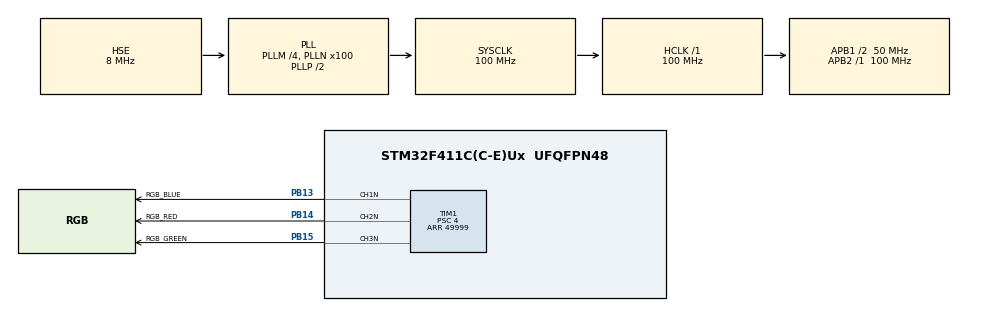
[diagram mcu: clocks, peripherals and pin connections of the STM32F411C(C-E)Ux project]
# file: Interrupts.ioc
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Mcu.Family=STM32F4
Mcu.Name=STM32F411C(C-E)Ux
Mcu.Package=UFQFPN48
NVIC.PriorityGroup=NVIC_PRIORITYGROUP_4
NVIC.TIM1_UP_TIM10_IRQn=true\:0\:0\:false\:false\:true\:true\:true\:true
PB13.GPIO_Label=RGB_BLUE
PB13.Mode=PWM Generation1 CH1N
PB13.Signal=TIM1_CH1N
PB14.GPIO_Label=RGB_RED
PB14.Mode=PWM Generation2 CH2N
PB14.Signal=TIM1_CH2N
PB15.GPIO_Label=RGB_GREEN
PB15.Mode=PWM Generation3 CH3N
PB15.Signal=TIM1_CH3N
PH0\ -\ OSC_IN.Mode=HSE-External-Oscillator
PH0\ -\ OSC_IN.Signal=RCC_OSC_IN
PH1\ -\ OSC_OUT.Mode=HSE-External-Oscillator
PH1\ -\ OSC_OUT.Signal=RCC_OSC_OUT
ProjectManager.HeapSize=0x200
ProjectManager.StackSize=0x400
ProjectManager.TargetToolchain=STM32CubeIDE
RCC.48MHZClocksFreq_Value=50000000
RCC.AHBFreq_Value=100000000
RCC.APB1CLKDivider=RCC_HCLK_DIV2
RCC.APB1Freq_Value=50000000
RCC.APB1TimFreq_Value=100000000
RCC.APB2Freq_Value=100000000
RCC.APB2TimFreq_Value=100000000
RCC.CortexFreq_Value=100000000
RCC.HCLKFreq_Value=100000000
RCC.HSE_VALUE=8000000
RCC.HSI_VALUE=16000000
RCC.LSE_VALUE=32768
RCC.PLLM=4
RCC.PLLN=100
RCC.PLLSourceVirtual=RCC_PLLSOURCE_HSE
RCC.SYSCLKFreq_VALUE=100000000
RCC.SYSCLKSource=RCC_SYSCLKSOURCE_PLLCLK
RCC.VCOOutputFreq_Value=200000000
TIM1.Channel-PWM\ Generation1\ CH1N=TIM_CHANNEL_1
TIM1.Channel-PWM\ Generation2\ CH2N=TIM_CHANNEL_2
TIM1.Channel-PWM\ Generation3\ CH3N=TIM_CHANNEL_3
TIM1.OCNPolarity_1=TIM_OCNPOLARITY_LOW
TIM1.OCNPolarity_2=TIM_OCNPOLARITY_LOW
TIM1.OCNPolarity_3=TIM_OCNPOLARITY_LOW
TIM1.Period=49999
TIM1.Prescaler=4
TIM10.Period=9999
TIM10.Prescaler=99
VP_TIM10_VS_ClockSourceINT.Mode=Enable_Timer
VP_TIM1_VS_ClockSourceINT.Mode=Internal
board=custom

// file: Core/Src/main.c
/* USER CODE BEGIN Header */
/**
  ******************************************************************************
  * @file           : main.c
  * @brief          : Main program body
  ******************************************************************************
  * @attention
  *
  * Copyright (c) 2024 STMicroelectronics.
  * All rights reserved.
  *
  * This software is licensed under terms that can be found in the LICENSE file
  * in the root directory of this software component.
  * If no LICENSE file comes with this software, it is provided AS-IS.
  *
  ******************************************************************************
  */
/* USER CODE END Header */
#include "main.h"

TIM_HandleTypeDef htim1;
TIM_HandleTypeDef htim10;

/* USER CODE BEGIN PV */
int Red =10000,Green=20000,Blue=30000;
/* USER CODE END PV */

void SystemClock_Config(void);
static void MX_GPIO_Init(void);
static void MX_TIM1_Init(void);
static void MX_TIM10_Init(void);

/* USER CODE BEGIN 0 */
void HAL_TIM_PeriodElapsedCallback(TIM_HandleTypeDef *htim)
 {
	 __HAL_TIM_SET_COMPARE(&htim1,TIM_CHANNEL_1,Red);
	 __HAL_TIM_SET_COMPARE(&htim1,TIM_CHANNEL_2,Green);
	 __HAL_TIM_SET_COMPARE(&htim1,TIM_CHANNEL_3,Blue);
	 Red = Red +20;
	 Green = Green+20;
	 Blue=Blue +20;
	 if (Red>49999)Red=0;
	 if (Green>4999)Green=0;
	 if (Blue>4999)Blue=0;

 }
/* USER CODE END 0 */

int main(void)
{

  /* MCU Configuration--------------------------------------------------------*/

  /* Reset of all peripherals, Initializes the Flash interface and the Systick. */
  HAL_Init();

  /* Configure the system clock */
  SystemClock_Config();

  /* Initialize all configured peripherals */
  MX_GPIO_Init();
  MX_TIM1_Init();
  MX_TIM10_Init();
  /* USER CODE BEGIN 2 */

HAL_TIMEx_PWMN_Start(&htim1, TIM_CHANNEL_1);
HAL_TIMEx_PWMN_Start(&htim1, TIM_CHANNEL_2);
HAL_TIMEx_PWMN_Start(&htim1, TIM_CHANNEL_3);

HAL_TIM_Base_Start_IT(&htim10);
  /* USER CODE END 2 */

  /* Infinite loop */
  while (1)
  {

  }
}

void SystemClock_Config(void)
{
  RCC_OscInitTypeDef RCC_OscInitStruct = {0};
  RCC_ClkInitTypeDef RCC_ClkInitStruct = {0};

  /** Configure the main internal regulator output voltage
  */
  __HAL_RCC_PWR_CLK_ENABLE();
  __HAL_PWR_VOLTAGESCALING_CONFIG(PWR_REGULATOR_VOLTAGE_SCALE1);

  /** Initializes the RCC Oscillators according to the specified parameters
  * in the RCC_OscInitTypeDef structure.
  */
  RCC_OscInitStruct.OscillatorType = RCC_OSCILLATORTYPE_HSE;
  RCC_OscInitStruct.HSEState = RCC_HSE_ON;
  RCC_OscInitStruct.PLL.PLLState = RCC_PLL_ON;
  RCC_OscInitStruct.PLL.PLLSource = RCC_PLLSOURCE_HSE;
  RCC_OscInitStruct.PLL.PLLM = 4;
  RCC_OscInitStruct.PLL.PLLN = 100;
  RCC_OscInitStruct.PLL.PLLP = RCC_PLLP_DIV2;
  RCC_OscInitStruct.PLL.PLLQ = 4;
  if (HAL_RCC_OscConfig(&RCC_OscInitStruct) != HAL_OK)
  {
    Error_Handler();
  }

  /** Initializes the CPU, AHB and APB buses clocks
  */
  RCC_ClkInitStruct.ClockType = RCC_CLOCKTYPE_HCLK|RCC_CLOCKTYPE_SYSCLK
                              |RCC_CLOCKTYPE_PCLK1|RCC_CLOCKTYPE_PCLK2;
  RCC_ClkInitStruct.SYSCLKSource = RCC_SYSCLKSOURCE_PLLCLK;
  RCC_ClkInitStruct.AHBCLKDivider = RCC_SYSCLK_DIV1;
  RCC_ClkInitStruct.APB1CLKDivider = RCC_HCLK_DIV2;
  RCC_ClkInitStruct.APB2CLKDivider = RCC_HCLK_DIV1;

  if (HAL_RCC_ClockConfig(&RCC_ClkInitStruct, FLASH_LATENCY_3) != HAL_OK)
  {
    Error_Handler();
  }
}

static void MX_TIM1_Init(void)
{

  TIM_ClockConfigTypeDef sClockSourceConfig = {0};
  TIM_MasterConfigTypeDef sMasterConfig = {0};
  TIM_OC_InitTypeDef sConfigOC = {0};
  TIM_BreakDeadTimeConfigTypeDef sBreakDeadTimeConfig = {0};

  htim1.Instance = TIM1;
  htim1.Init.Prescaler = 4;
  htim1.Init.CounterMode = TIM_COUNTERMODE_UP;
  htim1.Init.Period = 49999;
  htim1.Init.ClockDivision = TIM_CLOCKDIVISION_DIV1;
  htim1.Init.RepetitionCounter = 0;
  htim1.Init.AutoReloadPreload = TIM_AUTORELOAD_PRELOAD_DISABLE;
  if (HAL_TIM_Base_Init(&htim1) != HAL_OK)
  {
    Error_Handler();
  }
  sClockSourceConfig.ClockSource = TIM_CLOCKSOURCE_INTERNAL;
  if (HAL_TIM_ConfigClockSource(&htim1, &sClockSourceConfig) != HAL_OK)
  {
    Error_Handler();
  }
  if (HAL_TIM_PWM_Init(&htim1) != HAL_OK)
  {
    Error_Handler();
  }
  sMasterConfig.MasterOutputTrigger = TIM_TRGO_RESET;
  sMasterConfig.MasterSlaveMode = TIM_MASTERSLAVEMODE_DISABLE;
  if (HAL_TIMEx_MasterConfigSynchronization(&htim1, &sMasterConfig) != HAL_OK)
  {
    Error_Handler();
  }
  sConfigOC.OCMode = TIM_OCMODE_PWM1;
  sConfigOC.Pulse = 0;
  sConfigOC.OCPolarity = TIM_OCPOLARITY_HIGH;
  sConfigOC.OCNPolarity = TIM_OCNPOLARITY_LOW;
  sConfigOC.OCFastMode = TIM_OCFAST_DISABLE;
  sConfigOC.OCIdleState = TIM_OCIDLESTATE_RESET;
  sConfigOC.OCNIdleState = TIM_OCNIDLESTATE_RESET;
  if (HAL_TIM_PWM_ConfigChannel(&htim1, &sConfigOC, TIM_CHANNEL_1) != HAL_OK)
  {
    Error_Handler();
  }
  if (HAL_TIM_PWM_ConfigChannel(&htim1, &sConfigOC, TIM_CHANNEL_2) != HAL_OK)
  {
    Error_Handler();
  }
  if (HAL_TIM_PWM_ConfigChannel(&htim1, &sConfigOC, TIM_CHANNEL_3) != HAL_OK)
  {
    Error_Handler();
  }
  sBreakDeadTimeConfig.OffStateRunMode = TIM_OSSR_DISABLE;
  sBreakDeadTimeConfig.OffStateIDLEMode = TIM_OSSI_DISABLE;
  sBreakDeadTimeConfig.LockLevel = TIM_LOCKLEVEL_OFF;
  sBreakDeadTimeConfig.DeadTime = 0;
  sBreakDeadTimeConfig.BreakState = TIM_BREAK_DISABLE;
  sBreakDeadTimeConfig.BreakPolarity = TIM_BREAKPOLARITY_HIGH;
  sBreakDeadTimeConfig.AutomaticOutput = TIM_AUTOMATICOUTPUT_DISABLE;
  if (HAL_TIMEx_ConfigBreakDeadTime(&htim1, &sBreakDeadTimeConfig) != HAL_OK)
  {
    Error_Handler();
  }
  HAL_TIM_MspPostInit(&htim1);

}

static void MX_TIM10_Init(void)
{

  htim10.Instance = TIM10;
  htim10.Init.Prescaler = 99;
  htim10.Init.CounterMode = TIM_COUNTERMODE_UP;
  htim10.Init.Period = 9999;
  htim10.Init.ClockDivision = TIM_CLOCKDIVISION_DIV1;
  htim10.Init.AutoReloadPreload = TIM_AUTORELOAD_PRELOAD_DISABLE;
  if (HAL_TIM_Base_Init(&htim10) != HAL_OK)
  {
    Error_Handler();
  }

}

static void MX_GPIO_Init(void)
{

  /* GPIO Ports Clock Enable */
  __HAL_RCC_GPIOH_CLK_ENABLE();
  __HAL_RCC_GPIOB_CLK_ENABLE();

}

void Error_Handler(void)
{
  __disable_irq();
  while (1)
  {
  }
}
